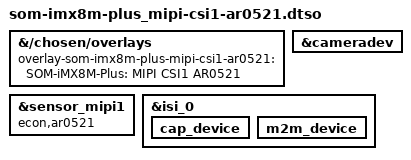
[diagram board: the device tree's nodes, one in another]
#include "overlay.h"

&{/chosen/overlays} {
	overlay-som-imx8m-plus-mipi-csi1-ar0521 = "SOM-iMX8M-Plus: MIPI CSI1 AR0521";
};

#include "som-imx8m-plus_mipi-csi1.dtsi"

&sensor_mipi1 {
	compatible = "econ,ar0521", "ar0521";
};

&cameradev {
	status = "okay";
};

&isi_0 {
	status = "okay";

	cap_device {
		status = "okay";
	};

	m2m_device {
		status = "okay";
	};
};
